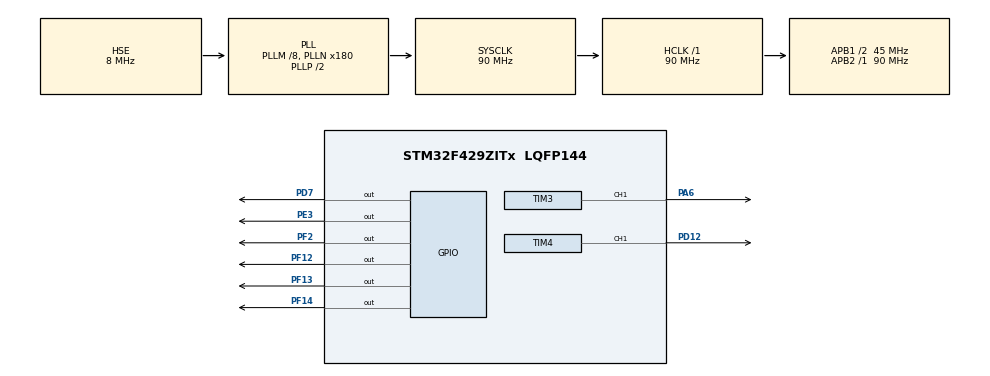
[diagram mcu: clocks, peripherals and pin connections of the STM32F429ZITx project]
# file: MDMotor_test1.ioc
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Mcu.Family=STM32F4
Mcu.Name=STM32F429ZITx
Mcu.Package=LQFP144
NVIC.PriorityGroup=NVIC_PRIORITYGROUP_4
NVIC.TIM4_IRQn=true\:0\:0\:false\:false\:true\:true\:true\:true
PA13.Mode=Serial_Wire
PA13.Signal=SYS_JTMS-SWDIO
PA14.Mode=Serial_Wire
PA14.Signal=SYS_JTCK-SWCLK
PA6.Signal=S_TIM3_CH1
PD12.Signal=S_TIM4_CH1
PD7.GPIO_ModeDefaultOutputPP=GPIO_MODE_OUTPUT_PP
PD7.GPIO_PuPd=GPIO_PULLUP
PD7.GPIO_Speed=GPIO_SPEED_FREQ_HIGH
PD7.PinState=GPIO_PIN_RESET
PD7.Signal=GPIO_Output
PE3.GPIO_ModeDefaultOutputPP=GPIO_MODE_OUTPUT_PP
PE3.GPIO_PuPd=GPIO_PULLUP
PE3.GPIO_Speed=GPIO_SPEED_FREQ_HIGH
PE3.PinState=GPIO_PIN_RESET
PE3.Signal=GPIO_Output
PF12.GPIO_ModeDefaultOutputPP=GPIO_MODE_OUTPUT_PP
PF12.GPIO_PuPd=GPIO_PULLUP
PF12.GPIO_Speed=GPIO_SPEED_FREQ_HIGH
PF12.PinState=GPIO_PIN_RESET
PF12.Signal=GPIO_Output
PF13.GPIO_ModeDefaultOutputPP=GPIO_MODE_OUTPUT_PP
PF13.GPIO_PuPd=GPIO_PULLUP
PF13.GPIO_Speed=GPIO_SPEED_FREQ_HIGH
PF13.PinState=GPIO_PIN_RESET
PF13.Signal=GPIO_Output
PF14.GPIO_ModeDefaultOutputPP=GPIO_MODE_OUTPUT_PP
PF14.GPIO_PuPd=GPIO_PULLUP
PF14.GPIO_Speed=GPIO_SPEED_FREQ_HIGH
PF14.PinState=GPIO_PIN_RESET
PF14.Signal=GPIO_Output
PF2.GPIO_ModeDefaultOutputPP=GPIO_MODE_OUTPUT_PP
PF2.GPIO_PuPd=GPIO_PULLUP
PF2.GPIO_Speed=GPIO_SPEED_FREQ_HIGH
PF2.PinState=GPIO_PIN_RESET
PF2.Signal=GPIO_Output
PH0/OSC_IN.Mode=HSE-External-Clock-Source
PH0/OSC_IN.Signal=RCC_OSC_IN
PH1/OSC_OUT.Mode=HSE-External-Clock-Source
PH1/OSC_OUT.Signal=RCC_OSC_OUT
ProjectManager.HeapSize=0x200
ProjectManager.StackSize=0x400
ProjectManager.TargetToolchain=STM32CubeIDE
RCC.48MHZClocksFreq_Value=45000000
RCC.AHBFreq_Value=90000000
RCC.APB1CLKDivider=RCC_HCLK_DIV2
RCC.APB1Freq_Value=45000000
RCC.APB1TimFreq_Value=90000000
RCC.APB2Freq_Value=90000000
RCC.APB2TimFreq_Value=90000000
RCC.CortexFreq_Value=90000000
RCC.HCLKFreq_Value=90000000
RCC.HSE_VALUE=8000000
RCC.HSI_VALUE=16000000
RCC.LSE_VALUE=32768
RCC.PLLM=8
RCC.PLLN=180
RCC.PLLSourceVirtual=RCC_PLLSOURCE_HSE
RCC.SYSCLKFreq_VALUE=90000000
RCC.SYSCLKSource=RCC_SYSCLKSOURCE_PLLCLK
RCC.VCOOutputFreq_Value=180000000
SH.S_TIM3_CH1.0=TIM3_CH1,PWM Generation1 CH1
SH.S_TIM4_CH1.0=TIM4_CH1,PWM Generation1 CH1
TIM3.Channel-PWM\ Generation1\ CH1=TIM_CHANNEL_1
TIM3.Period=99
TIM3.Prescaler=89
TIM3.Pulse-PWM\ Generation1\ CH1=89
TIM4.Channel-PWM\ Generation1\ CH1=TIM_CHANNEL_1
TIM4.Period=99
TIM4.Prescaler=89
TIM4.Pulse-PWM\ Generation1\ CH1=89
VP_TIM3_VS_ClockSourceINT.Mode=Internal
VP_TIM4_VS_ClockSourceINT.Mode=Internal
board=custom

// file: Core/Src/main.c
/* USER CODE BEGIN Header */
/**
  ******************************************************************************
  * @file           : main.c
  * @brief          : Main program body
  ******************************************************************************
  * @attention
  *
  * Copyright (c) 2024 STMicroelectronics.
  * All rights reserved.
  *
  * This software is licensed under terms that can be found in the LICENSE file
  * in the root directory of this software component.
  * If no LICENSE file comes with this software, it is provided AS-IS.
  *
  ******************************************************************************
  */
/* USER CODE END Header */
#include "main.h"

TIM_HandleTypeDef htim3;
TIM_HandleTypeDef htim4;

void SystemClock_Config(void);
static void MX_GPIO_Init(void);
static void MX_TIM3_Init(void);
static void MX_TIM4_Init(void);
/* USER CODE BEGIN PFP */

void LED_OnOff(int, int);

/* USER CODE END PFP */

int main(void)
{

  /* MCU Configuration--------------------------------------------------------*/

  /* Reset of all peripherals, Initializes the Flash interface and the Systick. */
  HAL_Init();

  /* Configure the system clock */
  SystemClock_Config();

  /* Initialize all configured peripherals */
  MX_GPIO_Init();
  MX_TIM3_Init();
  MX_TIM4_Init();
  /* USER CODE BEGIN 2 */

//  LED_OnOff(LED_ALL, 500);
  HAL_TIM_Base_Start_IT(&htim3);
  HAL_TIM_PWM_Start(&htim3, TIM_CHANNEL_1);
  HAL_TIM_Base_Start_IT(&htim4);
  HAL_TIM_PWM_Start(&htim4, TIM_CHANNEL_1);

//  HAL_GPIO_WritePin(GPIOF, GPIO_PIN_12, RESET);
//  HAL_GPIO_WritePin(GPIOF, GPIO_PIN_13, RESET);
//  HAL_GPIO_WritePin(GPIOF, GPIO_PIN_14, RESET);

//  HAL_GPIO_WritePin(GPIOF, GPIO_PIN_2, RESET);
//  HAL_GPIO_WritePin(GPIOD, GPIO_PIN_7, RESET);
//  HAL_GPIO_WritePin(GPIOE, GPIO_PIN_3, RESET);

  HAL_GPIO_WritePin(GPIOF, GPIO_PIN_12, SET);
  HAL_GPIO_WritePin(GPIOF, GPIO_PIN_13, SET);
  HAL_GPIO_WritePin(GPIOF, GPIO_PIN_14, SET);

  HAL_GPIO_WritePin(GPIOF, GPIO_PIN_2, SET);
  HAL_GPIO_WritePin(GPIOD, GPIO_PIN_7, SET);
  HAL_GPIO_WritePin(GPIOE, GPIO_PIN_3, SET);

  /* USER CODE END 2 */

  /* Infinite loop */
  while (1)
  {

  }
}

void SystemClock_Config(void)
{
  RCC_OscInitTypeDef RCC_OscInitStruct = {0};
  RCC_ClkInitTypeDef RCC_ClkInitStruct = {0};

  /** Configure the main internal regulator output voltage
  */
  __HAL_RCC_PWR_CLK_ENABLE();
  __HAL_PWR_VOLTAGESCALING_CONFIG(PWR_REGULATOR_VOLTAGE_SCALE3);

  /** Initializes the RCC Oscillators according to the specified parameters
  * in the RCC_OscInitTypeDef structure.
  */
  RCC_OscInitStruct.OscillatorType = RCC_OSCILLATORTYPE_HSE;
  RCC_OscInitStruct.HSEState = RCC_HSE_BYPASS;
  RCC_OscInitStruct.PLL.PLLState = RCC_PLL_ON;
  RCC_OscInitStruct.PLL.PLLSource = RCC_PLLSOURCE_HSE;
  RCC_OscInitStruct.PLL.PLLM = 8;
  RCC_OscInitStruct.PLL.PLLN = 180;
  RCC_OscInitStruct.PLL.PLLP = RCC_PLLP_DIV2;
  RCC_OscInitStruct.PLL.PLLQ = 4;
  if (HAL_RCC_OscConfig(&RCC_OscInitStruct) != HAL_OK)
  {
    Error_Handler();
  }

  /** Activate the Over-Drive mode
  */
  if (HAL_PWREx_EnableOverDrive() != HAL_OK)
  {
    Error_Handler();
  }

  /** Initializes the CPU, AHB and APB buses clocks
  */
  RCC_ClkInitStruct.ClockType = RCC_CLOCKTYPE_HCLK|RCC_CLOCKTYPE_SYSCLK
                              |RCC_CLOCKTYPE_PCLK1|RCC_CLOCKTYPE_PCLK2;
  RCC_ClkInitStruct.SYSCLKSource = RCC_SYSCLKSOURCE_PLLCLK;
  RCC_ClkInitStruct.AHBCLKDivider = RCC_SYSCLK_DIV1;
  RCC_ClkInitStruct.APB1CLKDivider = RCC_HCLK_DIV2;
  RCC_ClkInitStruct.APB2CLKDivider = RCC_HCLK_DIV1;

  if (HAL_RCC_ClockConfig(&RCC_ClkInitStruct, FLASH_LATENCY_2) != HAL_OK)
  {
    Error_Handler();
  }
}

static void MX_TIM3_Init(void)
{

  TIM_ClockConfigTypeDef sClockSourceConfig = {0};
  TIM_MasterConfigTypeDef sMasterConfig = {0};
  TIM_OC_InitTypeDef sConfigOC = {0};

  htim3.Instance = TIM3;
  htim3.Init.Prescaler = 89;
  htim3.Init.CounterMode = TIM_COUNTERMODE_UP;
  htim3.Init.Period = 99;
  htim3.Init.ClockDivision = TIM_CLOCKDIVISION_DIV1;
  htim3.Init.AutoReloadPreload = TIM_AUTORELOAD_PRELOAD_DISABLE;
  if (HAL_TIM_Base_Init(&htim3) != HAL_OK)
  {
    Error_Handler();
  }
  sClockSourceConfig.ClockSource = TIM_CLOCKSOURCE_INTERNAL;
  if (HAL_TIM_ConfigClockSource(&htim3, &sClockSourceConfig) != HAL_OK)
  {
    Error_Handler();
  }
  if (HAL_TIM_PWM_Init(&htim3) != HAL_OK)
  {
    Error_Handler();
  }
  sMasterConfig.MasterOutputTrigger = TIM_TRGO_RESET;
  sMasterConfig.MasterSlaveMode = TIM_MASTERSLAVEMODE_DISABLE;
  if (HAL_TIMEx_MasterConfigSynchronization(&htim3, &sMasterConfig) != HAL_OK)
  {
    Error_Handler();
  }
  sConfigOC.OCMode = TIM_OCMODE_PWM1;
  sConfigOC.Pulse = 89;
  sConfigOC.OCPolarity = TIM_OCPOLARITY_HIGH;
  sConfigOC.OCFastMode = TIM_OCFAST_DISABLE;
  if (HAL_TIM_PWM_ConfigChannel(&htim3, &sConfigOC, TIM_CHANNEL_1) != HAL_OK)
  {
    Error_Handler();
  }
  HAL_TIM_MspPostInit(&htim3);

}

static void MX_TIM4_Init(void)
{

  TIM_ClockConfigTypeDef sClockSourceConfig = {0};
  TIM_MasterConfigTypeDef sMasterConfig = {0};
  TIM_OC_InitTypeDef sConfigOC = {0};

  htim4.Instance = TIM4;
  htim4.Init.Prescaler = 89;
  htim4.Init.CounterMode = TIM_COUNTERMODE_UP;
  htim4.Init.Period = 99;
  htim4.Init.ClockDivision = TIM_CLOCKDIVISION_DIV1;
  htim4.Init.AutoReloadPreload = TIM_AUTORELOAD_PRELOAD_DISABLE;
  if (HAL_TIM_Base_Init(&htim4) != HAL_OK)
  {
    Error_Handler();
  }
  sClockSourceConfig.ClockSource = TIM_CLOCKSOURCE_INTERNAL;
  if (HAL_TIM_ConfigClockSource(&htim4, &sClockSourceConfig) != HAL_OK)
  {
    Error_Handler();
  }
  if (HAL_TIM_PWM_Init(&htim4) != HAL_OK)
  {
    Error_Handler();
  }
  sMasterConfig.MasterOutputTrigger = TIM_TRGO_RESET;
  sMasterConfig.MasterSlaveMode = TIM_MASTERSLAVEMODE_DISABLE;
  if (HAL_TIMEx_MasterConfigSynchronization(&htim4, &sMasterConfig) != HAL_OK)
  {
    Error_Handler();
  }
  sConfigOC.OCMode = TIM_OCMODE_PWM1;
  sConfigOC.Pulse = 89;
  sConfigOC.OCPolarity = TIM_OCPOLARITY_HIGH;
  sConfigOC.OCFastMode = TIM_OCFAST_DISABLE;
  if (HAL_TIM_PWM_ConfigChannel(&htim4, &sConfigOC, TIM_CHANNEL_1) != HAL_OK)
  {
    Error_Handler();
  }
  HAL_TIM_MspPostInit(&htim4);

}

static void MX_GPIO_Init(void)
{
  GPIO_InitTypeDef GPIO_InitStruct = {0};

  /* GPIO Ports Clock Enable */
  __HAL_RCC_GPIOE_CLK_ENABLE();
  __HAL_RCC_GPIOF_CLK_ENABLE();
  __HAL_RCC_GPIOH_CLK_ENABLE();
  __HAL_RCC_GPIOA_CLK_ENABLE();
  __HAL_RCC_GPIOD_CLK_ENABLE();

  /*Configure GPIO pin Output Level */
  HAL_GPIO_WritePin(GPIOE, GPIO_PIN_3, GPIO_PIN_RESET);

  /*Configure GPIO pin Output Level */
  HAL_GPIO_WritePin(GPIOF, GPIO_PIN_2|GPIO_PIN_12|GPIO_PIN_13|GPIO_PIN_14, GPIO_PIN_RESET);

  /*Configure GPIO pin Output Level */
  HAL_GPIO_WritePin(GPIOD, GPIO_PIN_7, GPIO_PIN_RESET);

  /*Configure GPIO pin : PE3 */
  GPIO_InitStruct.Pin = GPIO_PIN_3;
  GPIO_InitStruct.Mode = GPIO_MODE_OUTPUT_PP;
  GPIO_InitStruct.Pull = GPIO_PULLUP;
  GPIO_InitStruct.Speed = GPIO_SPEED_FREQ_HIGH;
  HAL_GPIO_Init(GPIOE, &GPIO_InitStruct);

  /*Configure GPIO pins : PF2 PF12 PF13 PF14 */
  GPIO_InitStruct.Pin = GPIO_PIN_2|GPIO_PIN_12|GPIO_PIN_13|GPIO_PIN_14;
  GPIO_InitStruct.Mode = GPIO_MODE_OUTPUT_PP;
  GPIO_InitStruct.Pull = GPIO_PULLUP;
  GPIO_InitStruct.Speed = GPIO_SPEED_FREQ_HIGH;
  HAL_GPIO_Init(GPIOF, &GPIO_InitStruct);

  /*Configure GPIO pin : PD7 */
  GPIO_InitStruct.Pin = GPIO_PIN_7;
  GPIO_InitStruct.Mode = GPIO_MODE_OUTPUT_PP;
  GPIO_InitStruct.Pull = GPIO_PULLUP;
  GPIO_InitStruct.Speed = GPIO_SPEED_FREQ_HIGH;
  HAL_GPIO_Init(GPIOD, &GPIO_InitStruct);

}

/* USER CODE BEGIN 4 */
/*
void LED_OnOff(int led, int interval)
{
	HAL_GPIO_WritePin(GPIO_LED, led, GPIO_PIN_SET );
	HAL_GPIO_WritePin(GPIO_LED_Nucleo, led, GPIO_PIN_SET );
	HAL_Delay(interval);
	HAL_GPIO_WritePin(GPIO_LED, led, GPIO_PIN_RESET );
	HAL_GPIO_WritePin(GPIO_LED_Nucleo, led, GPIO_PIN_RESET );
}*/
/*
void HAL_TIM_PeriodElapsedCallback(TIM_HandleTypeDef *htim)
{
	HAL_GPIO_TogglePin(GPIO_LED, LED_ALL);
}
*/
/* USER CODE END 4 */

void Error_Handler(void)
{
  __disable_irq();
  while (1)
  {
  }
}
